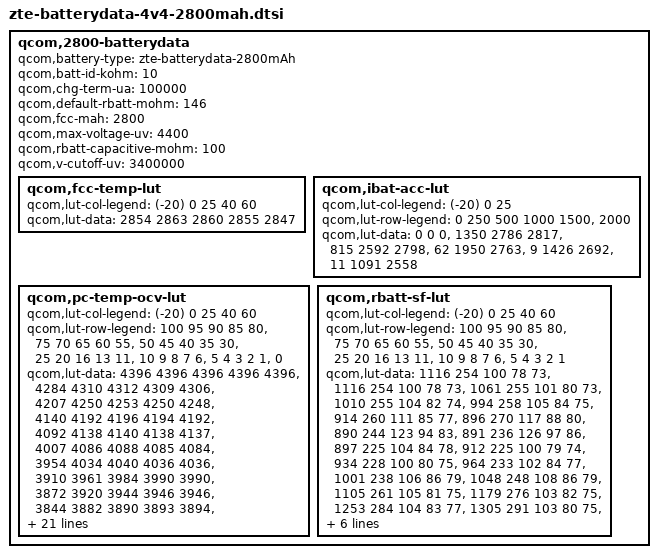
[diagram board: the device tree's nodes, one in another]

qcom,2800-batterydata {
	qcom,battery-type = "zte-batterydata-2800mAh";
	qcom,batt-id-kohm = <10>;
	qcom,chg-term-ua = <100000>;
	qcom,default-rbatt-mohm = <146>;
	qcom,fcc-mah = <2800>;
	qcom,max-voltage-uv = <4400>;
	qcom,rbatt-capacitive-mohm = <100>;
	qcom,v-cutoff-uv = <3400000>;

	qcom,fcc-temp-lut {
		qcom,lut-col-legend = <(-20) 0 25 40 60>;
		qcom,lut-data = <2854 2863 2860 2855 2847>;
	};

	qcom,ibat-acc-lut {
		qcom,lut-col-legend = <(-20) 0 25>;
		qcom,lut-row-legend = <0 250 500 1000 1500>,
					<2000>;
		qcom,lut-data = <0 0 0>,
				<1350 2786 2817>,
				<815 2592 2798>,
				<62 1950 2763>,
				<9 1426 2692>,
				<11 1091 2558>;
	};

	qcom,pc-temp-ocv-lut {
		qcom,lut-col-legend = <(-20) 0 25 40 60>;
		qcom,lut-row-legend = <100 95 90 85 80>,
					<75 70 65 60 55>,
					<50 45 40 35 30>,
					<25 20 16 13 11>,
					<10 9 8 7 6>,
					<5 4 3 2 1>,
					<0>;
		qcom,lut-data = <4396 4396 4396 4396 4396>,
				<4284 4310 4312 4309 4306>,
				<4207 4250 4253 4250 4248>,
				<4140 4192 4196 4194 4192>,
				<4092 4138 4140 4138 4137>,
				<4007 4086 4088 4085 4084>,
				<3954 4034 4040 4036 4036>,
				<3910 3961 3984 3990 3990>,
				<3872 3920 3944 3946 3946>,
				<3844 3882 3890 3893 3894>,
				<3822 3850 3856 3856 3857>,
				<3804 3825 3830 3830 3831>,
				<3788 3803 3809 3810 3809>,
				<3772 3788 3791 3792 3791>,
				<3756 3774 3776 3773 3770>,
				<3742 3761 3759 3750 3739>,
				<3726 3744 3740 3729 3716>,
				<3713 3723 3720 3710 3696>,
				<3700 3706 3700 3689 3677>,
				<3688 3700 3691 3682 3670>,
				<3682 3696 3690 3680 3668>,
				<3673 3694 3688 3679 3667>,
				<3663 3690 3686 3677 3665>,
				<3649 3687 3684 3674 3662>,
				<3630 3678 3678 3666 3651>,
				<3606 3657 3656 3640 3622>,
				<3570 3616 3610 3594 3576>,
				<3521 3557 3550 3533 3516>,
				<3448 3473 3468 3451 3434>,
				<3321 3339 3342 3328 3312>,
				<3014 3000 3059 3031 3000>;
	};

	qcom,rbatt-sf-lut {
		qcom,lut-col-legend = <(-20) 0 25 40 60>;
		qcom,lut-row-legend = <100 95 90 85 80>,
					<75 70 65 60 55>,
					<50 45 40 35 30>,
					<25 20 16 13 11>,
					<10 9 8 7 6>,
					<5 4 3 2 1>;
		qcom,lut-data = <1116 254 100 78 73>,
				<1116 254 100 78 73>,
				<1061 255 101 80 73>,
				<1010 255 104 82 74>,
				<994 258 105 84 75>,
				<914 260 111 85 77>,
				<896 270 117 88 80>,
				<890 244 123 94 83>,
				<891 236 126 97 86>,
				<897 225 104 84 78>,
				<912 225 100 79 74>,
				<934 228 100 80 75>,
				<964 233 102 84 77>,
				<1001 238 106 86 79>,
				<1048 248 108 86 79>,
				<1105 261 105 81 75>,
				<1179 276 103 82 75>,
				<1253 284 104 83 77>,
				<1305 291 103 80 75>,
				<1300 295 103 80 75>,
				<1337 304 104 82 76>,
				<1377 314 107 84 78>,
				<1418 327 110 86 81>,
				<1466 345 114 90 85>,
				<1522 361 119 93 85>,
				<1589 373 115 86 79>,
				<1707 383 111 85 78>,
				<2064 412 115 86 80>,
				<2682 459 121 90 85>,
				<4282 904 167 112 111>;
	};
};
/* TEST_DB_ID=TEST_ID_NOT_SET */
